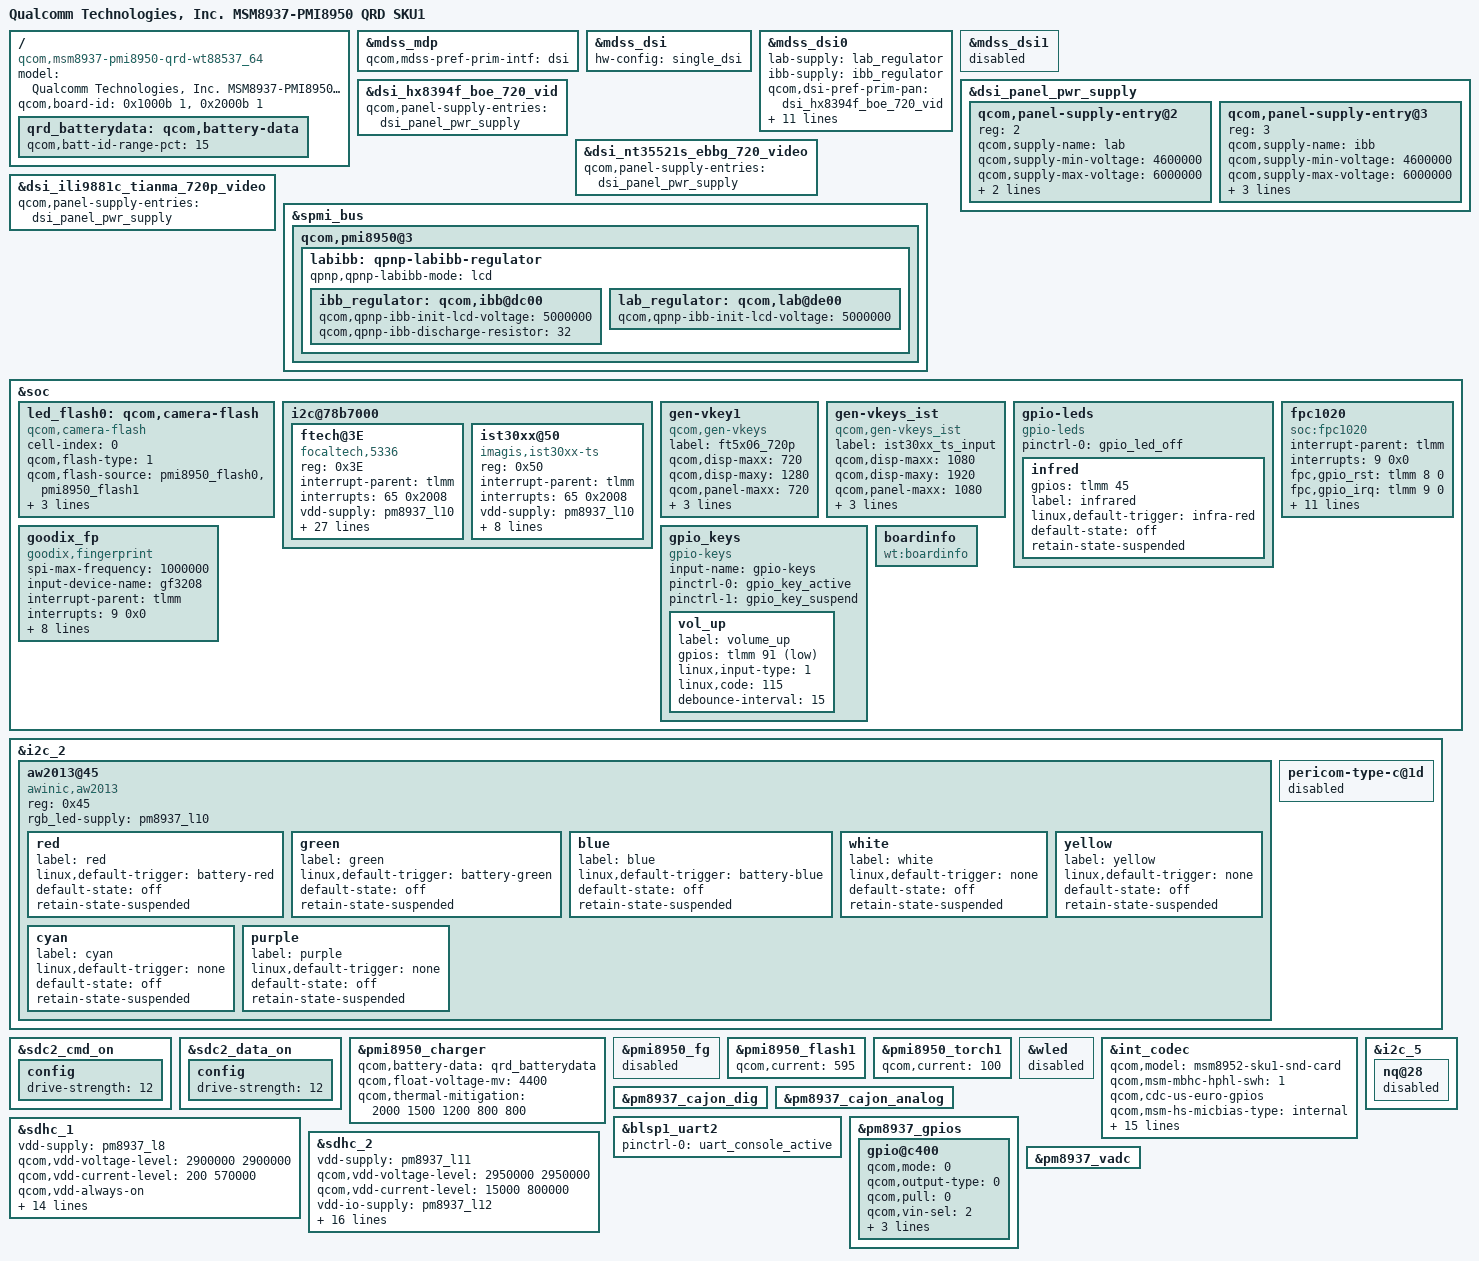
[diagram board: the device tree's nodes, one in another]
/*
 * Copyright (c) 2015, The Linux Foundation. All rights reserved.
 *
 * This program is free software; you can redistribute it and/or modify
 * it under the terms of the GNU General Public License version 2 and
 * only version 2 as published by the Free Software Foundation.
 *
 * This program is distributed in the hope that it will be useful,
 * but WITHOUT ANY WARRANTY; without even the implied warranty of
 * MERCHANTABILITY or FITNESS FOR A PARTICULAR PURPOSE.  See the
 * GNU General Public License for more details.
 */

/dts-v1/;

#include "msm8937.dtsi"
#include "msm-pmi8950.dtsi"
#include "msm8937-camera-sensor-qrd-land.dtsi"
#include "msm8937-mdss-panels.dtsi"
#include "msm8937-pinctrl.dtsi"

//display-panels-start//
#include "dsi-panel-hx8394f-boe-720p-video.dtsi"
#include "dsi-panel-nt35521s-ebbg-720p-video.dtsi"
#include "dsi-panel-ili9881c-tianma-720p-video.dtsi"

&mdss_mdp {
	qcom,mdss-pref-prim-intf = "dsi";
};

&mdss_dsi {
	hw-config = "single_dsi";
};

&mdss_dsi0 {
	lab-supply = <&lab_regulator>;
	ibb-supply = <&ibb_regulator>;

	qcom,dsi-pref-prim-pan = <&dsi_hx8394f_boe_720_vid>;
	qcom,dsi-pref-sub-pan = <&dsi_nt35521s_ebbg_720_video>;
	qcom,dsi-pref-sub1-pan = <&dsi_ili9881c_tianma_720p_video>;
	pinctrl-names = "mdss_default", "mdss_sleep";
	pinctrl-0 = <&mdss_dsi_active &mdss_te_active>;
	pinctrl-1 = <&mdss_dsi_suspend &mdss_te_suspend>;

	qcom,platform-te-gpio = <&tlmm 24 0>;
	qcom,platform-reset-gpio = <&tlmm 60 0>;

	qcom,regulator-ldo-mode;
	qcom,platform-regulator-settings = [ 00 01 01 00 20 07 00];

};

&mdss_dsi1 {
	status = "disabled";
};

&labibb {
	status = "ok";
	qpnp,qpnp-labibb-mode = "lcd";
};

&ibb_regulator {
	qcom,qpnp-ibb-discharge-resistor = <32>;
};

&dsi_panel_pwr_supply {
	qcom,panel-supply-entry@2 {
		reg = <2>;
		qcom,supply-name = "lab";
		qcom,supply-min-voltage = <4600000>;
		qcom,supply-max-voltage = <6000000>;
		qcom,supply-enable-load = <100000>;
		qcom,supply-disable-load = <100>;
	};

	qcom,panel-supply-entry@3 {
		reg = <3>;
		qcom,supply-name = "ibb";
		qcom,supply-min-voltage = <4600000>;
		qcom,supply-max-voltage = <6000000>;
		qcom,supply-enable-load = <100000>;
		qcom,supply-disable-load = <100>;
		qcom,supply-post-on-sleep = <20>;
	};
};

&dsi_hx8394f_boe_720_vid {
	qcom,panel-supply-entries = <&dsi_panel_pwr_supply>;
};

&dsi_nt35521s_ebbg_720_video {
	qcom,panel-supply-entries = <&dsi_panel_pwr_supply>;
};

&dsi_ili9881c_tianma_720p_video {
	qcom,panel-supply-entries = <&dsi_panel_pwr_supply>;
};


&spmi_bus {
	qcom,pmi8950@3 {
		labibb: qpnp-labibb-regulator {
			ibb_regulator: qcom,ibb@dc00 {
				/delete-property/
					qcom,qpnp-ibb-use-default-voltage;
				qcom,qpnp-ibb-init-lcd-voltage = <5000000>;
			};

			lab_regulator: qcom,lab@de00 {
				/delete-property/
					qcom,qpnp-ibb-use-default-voltage;
				qcom,qpnp-ibb-init-lcd-voltage = <5000000>;
			};
		};
	};
};
//display-panels-end//

/ {
	model = "Qualcomm Technologies, Inc. MSM8937-PMI8950 QRD SKU1";
	compatible = "qcom,msm8937-pmi8950-qrd-wt88537_64",
		   "qcom,msm8937-qrd", "qcom,msm8937", "qcom,qrd";
	qcom,board-id= <0x1000b 1>, <0x2000b 1>;

	qrd_batterydata: qcom,battery-data {
		qcom,batt-id-range-pct = <15>;
		#include "batterydata-qrd-Desay-4v4-4000mah.dtsi"
		#include "batterydata-qrd-Atl-4v4-4000mah.dtsi"
		#include "batterydata-qrd-Coslight-4v4-4000mah.dtsi"
		#include "batterydata-qrd-feimaotui-4v4-4000mah.dtsi"
	};
};

&soc {
	led_flash0: qcom,camera-flash {
		cell-index = <0>;
		compatible = "qcom,camera-flash";
		qcom,flash-type = <1>;
		qcom,flash-source = <&pmi8950_flash0 &pmi8950_flash1>;
		qcom,torch-source = <&pmi8950_torch0 &pmi8950_torch1>;
		qcom,switch-source = <&pmi8950_switch>;
	};

	i2c@78b7000 {
		status = "ok";
		ftech@3E {
			compatible = "focaltech,5336";
			reg = <0x3E>;
			interrupt-parent = <&tlmm>;
			interrupts = <65 0x2008>;
			vdd-supply = <&pm8937_l10>;
			vcc_i2c-supply = <&pm8937_l5>;
			/* pins used by touchscreen */
			pinctrl-names = "pmx_ts_active","pmx_ts_suspend",
				"pmx_ts_release";
			pinctrl-0 = <&ts_int_active &ts_reset_active>;
			pinctrl-1 = <&ts_int_suspend &ts_reset_suspend>;
			pinctrl-2 = <&ts_release>;
			ftech,name = "ft5336";
			ftech,family-id = <0x36>;
			ftech,reset-gpio = <&tlmm 64 0x00>;
			ftech,irq-gpio = <&tlmm 65 0x2008>;
			ftech,display-coords = <0 0 720 1280>;
			ftech,panel-coords = <0 0 720 1280>;
		        ftech,button-map= <139 172 158>; /* APP_SWITCH HOME BACK just like stock rom */
		        ftech,button-y-coord = <2040>;
                        ftech,button-x-coords = <120 500 900>;
			ftech,no-force-update;
			ftech,i2c-pull-up;
			ftech,group-id = <1>;
			ftech,hard-reset-delay-ms = <20>;
			ftech,soft-reset-delay-ms = <200>;
			ftech,num-max-touches = <10>;
			ftech,fw-delay-aa-ms = <30>;
			ftech,fw-delay-55-ms = <30>;
			ftech,fw-upgrade-id1 = <0x79>;
			ftech,fw-upgrade-id2 = <0x18>;
			ftech,fw-delay-readid-ms = <10>;
			ftech,fw-delay-era-flsh-ms = <2000>;
			ftech,fw-auto-cal;
			ftech,ignore-id-check;
		};

		ist30xx@50 {
			compatible = "imagis,ist30xx-ts";
			reg = <0x50>;
			interrupt-parent = <&tlmm>;
			interrupts = <65 0x2008>;
			vdd-supply = <&pm8937_l10>;
			vcc_i2c-supply = <&pm8937_l5>;
			/* pins used by touchscreen */
			pinctrl-names = "pmx_ts_active","pmx_ts_suspend",
				"pmx_ts_release";
			pinctrl-0 = <&ts_int_active &ts_reset_active>;
			pinctrl-1 = <&ts_int_suspend &ts_reset_suspend>;
			pinctrl-2 = <&ts_release>;
			ist30xx,name = "ist30xx";
			ist30xx,family-id = <0x36>;
			ist30xx,reset-gpio = <&tlmm 64 0x00>;
			ist30xx,irq-gpio = <&tlmm 65 0x2008>;
			};

	};

	gen-vkey1 {
		compatible = "qcom,gen-vkeys";
		label = "ft5x06_720p";
		qcom,disp-maxx = <720>;
		qcom,disp-maxy = <1280>;
		qcom,panel-maxx = <720>;
		qcom,panel-maxy = <1458>;
		qcom,key-codes = <139 172 158>;
		qcom,y-offset = <0>;
	};

	gen-vkeys_ist {
		compatible = "qcom,gen-vkeys_ist";
		label = "ist30xx_ts_input";
		qcom,disp-maxx = <1080>;
		qcom,disp-maxy = <1920>;
		qcom,panel-maxx = <1080>;
		qcom,panel-maxy = <2098>;
		qcom,key-codes = <139 172 158>;
		qcom,y-offset = <0>;
	};
	gpio-leds {
		compatible = "gpio-leds";
		status = "okay";
		pinctrl-names = "default";
		pinctrl-0 = <&gpio_led_off>;

		infred {
			gpios = <&tlmm 45 0>;
			label = "infrared";
			linux,default-trigger = "infra-red";
			default-state = "off";
			retain-state-suspended;
		};

	};
	fpc1020 {
		compatible = "soc:fpc1020";

		interrupt-parent = <&tlmm>;
		interrupts = <9 0x0>;

		fpc,gpio_rst    = <&tlmm 8 0>;
		fpc,gpio_irq    = <&tlmm 9 0>;

		vcc_spi-supply  = <&pm8937_l5>;
		vdd_ana-supply  = <&pm8937_l5>;
		vdd_io-supply   = <&pm8937_l5>;

		fpc,enable-on-boot;
		/delete-property/
		fpc,enable-wakeup;

		fpc,spi-max-frequency = <4800000>;

		/* Only for SPI Clock Handled by Linux */
		clock-names = "iface_clk", "core_clk";
		clocks = <&clock_gcc clk_gcc_blsp1_ahb_clk>,
				<&clock_gcc clk_gcc_blsp1_qup1_spi_apps_clk>;

		pinctrl-names = "fpc1020_spi_active",
			"fpc1020_reset_reset",
			"fpc1020_reset_active",
			"fpc1020_irq_active";

		pinctrl-0 = <&fpc_spi_active>;
		pinctrl-1 = <&fpc_reset_reset>;
		pinctrl-2 = <&fpc_reset_active>;
		pinctrl-3 = <&fpc_irq_active>;
	};
	goodix_fp {
		compatible = "goodix,fingerprint";
		spi-max-frequency = <1000000>;
		input-device-name = "gf3208";
		interrupt-parent = <&tlmm>;
		interrupts = <9 0x0>;

		goodix,gpio_reset    = <&tlmm 8 0>;
		goodix,gpio_irq      = <&tlmm 9 0>;

		clock-names = "iface_clk", "core_clk";
		clocks = <&clock_gcc clk_gcc_blsp1_ahb_clk>,
				<&clock_gcc clk_gcc_blsp1_qup1_spi_apps_clk>;

		pinctrl-names = "goodixfp_spi_active",
			"goodixfp_reset_reset",
			"goodixfp_reset_active",
			"goodixfp_irq_active";

		pinctrl-0 = <&goodix_spi_active>;
		pinctrl-1 = <&goodix_reset_reset>;
		pinctrl-2 = <&goodix_reset_active>;
		pinctrl-3 = <&goodix_irq_active>;
	};

};

&i2c_2  { /* i2c 6 */
	aw2013@45 { /*blink */
		compatible = "awinic,aw2013";
		reg = <0x45>;
		rgb_led-supply = <&pm8937_l10>;

		red {
			label = "red";
			linux,default-trigger = "battery-red";
			default-state = "off";
			retain-state-suspended;
		};

		green {
			label = "green";
			linux,default-trigger = "battery-green";
			default-state = "off";
			retain-state-suspended;
		};

		blue {
			label = "blue";
			linux,default-trigger = "battery-blue";
			default-state = "off";
			retain-state-suspended;
		};
		white {
			label = "white";
			linux,default-trigger = "none";
			default-state = "off";
			retain-state-suspended;
		};

		yellow {
			label = "yellow";
			linux,default-trigger = "none";
			default-state = "off";
			retain-state-suspended;
		};

		cyan {
			label = "cyan";
			linux,default-trigger = "none";
			default-state = "off";
			retain-state-suspended;
		};
		purple {
			label = "purple";
			linux,default-trigger = "none";
			default-state = "off";
			retain-state-suspended;
		};

	};

	pericom-type-c@1d {
		status="disabled";
	};
};

&sdc2_cmd_on {
	config {
		drive-strength = <12>;
	};
};

&sdc2_data_on {
	config {
		drive-strength = <12>;
	};
};

&pmi8950_charger {
	qcom,battery-data = <&qrd_batterydata>;
	qcom,float-voltage-mv = <4400>;
	qcom,thermal-mitigation = <2000 1500 1200 800 800>;
        status = "okay";
};

&pmi8950_fg {
        status = "disabled";
};

&pmi8950_flash1 {
                qcom,current = <595>;
};
&pmi8950_torch1 {
                qcom,current = <100>;
};

//qrd-common-start//
&soc {
	gpio_keys {
		compatible = "gpio-keys";
		input-name = "gpio-keys";
		pinctrl-names = "tlmm_gpio_key_active","tlmm_gpio_key_suspend";
		pinctrl-0 = <&gpio_key_active>;
		pinctrl-1 = <&gpio_key_suspend>;

		vol_up {
			label = "volume_up";
			gpios = <&tlmm 91 0x1>;
			linux,input-type = <1>;
			linux,code = <115>;
			debounce-interval = <15>;
		};
	};


	boardinfo {
		compatible = "wt:boardinfo";
	};
};

&wled {
	status="disabled";
};

//arch/arm/boot/dts/qcom/msm-audio.dtsi-start//
&int_codec {
	status = "okay";
	qcom,model = "msm8952-sku1-snd-card";
	qcom,msm-mbhc-hphl-swh = <1>;
	qcom,cdc-us-euro-gpios;
	qcom,msm-hs-micbias-type = "internal";
	ext-spk-amp-gpio = <&tlmm 124 0>;
	headset-gpio = <&tlmm 129 0>;
	qcom,audio-routing =
		"RX_BIAS", "MCLK",
		"SPK_RX_BIAS", "MCLK",
		"INT_LDO_H", "MCLK",
		"MIC BIAS External", "Handset Mic",
		"MIC BIAS Internal2", "Headset Mic",
		"MIC BIAS External", "Secondary Mic",
		"AMIC1", "MIC BIAS External",
		"AMIC2", "MIC BIAS Internal2",
		"AMIC3", "MIC BIAS External";
	qcom,msm-gpios =
		"pri_i2s";
	qcom,pinctrl-names =
		"all_off",
		"pri_i2s_act";
	pinctrl-names =
		"all_off",
		"pri_i2s_act";
	pinctrl-0 = <&cdc_pdm_lines_sus &cdc_pdm_lines_2_sus>;
	pinctrl-1 = <&cdc_pdm_lines_act &cdc_pdm_lines_2_act>;
};
//arch/arm/boot/dts/qcom/msm-audio.dtsi-end//

&pm8937_cajon_dig {
	status = "okay";
};

&pm8937_cajon_analog {
	status = "okay";
};

&blsp1_uart2 {
	status = "ok";
	pinctrl-names = "default";
	pinctrl-0 = <&uart_console_active>;
};

&sdhc_1 {
	/* device core power supply */
	vdd-supply = <&pm8937_l8>;
	qcom,vdd-voltage-level = <2900000 2900000>;
	qcom,vdd-current-level = <200 570000>;
	qcom,vdd-always-on;

	/* device communication power supply */
	vdd-io-supply = <&pm8937_l5>;
	qcom,vdd-io-always-on;
	qcom,vdd-io-lpm-sup;
	qcom,vdd-io-voltage-level = <1800000 1800000>;
	qcom,vdd-io-current-level = <200 325000>;

	pinctrl-names = "active", "sleep";
	pinctrl-0 = <&sdc1_clk_on &sdc1_cmd_on &sdc1_data_on &sdc1_rclk_on>;
	pinctrl-1 = <&sdc1_clk_off &sdc1_cmd_off &sdc1_data_off &sdc1_rclk_off>;

	qcom,clk-rates = <400000 20000000 25000000 50000000 100000000 192000000
								384000000>;
	qcom,nonremovable;
	qcom,bus-speed-mode = "HS400_1p8v", "HS200_1p8v", "DDR_1p8v";

	status = "ok";
};

&sdhc_2 {
	/* device core power supply */
	vdd-supply = <&pm8937_l11>;
	qcom,vdd-voltage-level = <2950000 2950000>;
	qcom,vdd-current-level = <15000 800000>;

	/* device communication power supply */
	vdd-io-supply = <&pm8937_l12>;
	qcom,vdd-io-voltage-level = <1800000 2950000>;
	qcom,vdd-io-current-level = <200 22000>;

	pinctrl-names = "active", "sleep";
	pinctrl-0 = <&sdc2_clk_on &sdc2_cmd_on &sdc2_data_on &sdc2_cd_on>;
	pinctrl-1 = <&sdc2_clk_off &sdc2_cmd_off &sdc2_data_off &sdc2_cd_off>;

	#address-cells = <0>;
	interrupt-parent = <&sdhc_2>;
	interrupts = <0 1 2>;
	#interrupt-cells = <1>;
	interrupt-map-mask = <0xffffffff>;
	interrupt-map = <0 &intc 0 125 0
		1 &intc 0 221 0
		2 &tlmm 67 0>;
	interrupt-names = "hc_irq", "pwr_irq", "status_irq";
	cd-gpios = <&tlmm 67 0x1>;

	qcom,clk-rates = <400000 20000000 25000000 50000000 100000000
								200000000>;
	qcom,bus-speed-mode = "SDR12", "SDR25", "SDR50", "DDR50", "SDR104";

	status = "ok";
};

&i2c_5 { /* BLSP2 QUP1 */
	nq@28 {
		status="disabled";
	};
};

&pm8937_gpios {
	gpio@c400 {
		qcom,mode = <0>;
		qcom,output-type = <0>;
		qcom,pull = <0>;
		qcom,vin-sel = <2>;
		qcom,out-strength = <3>;
		qcom,src-sel = <0>;
		qcom,master-en = <1>;
		status = "okay";
	};
};

&pm8937_vadc {
	/delete-node/ chan@11;
};
//qrd-common-end//

